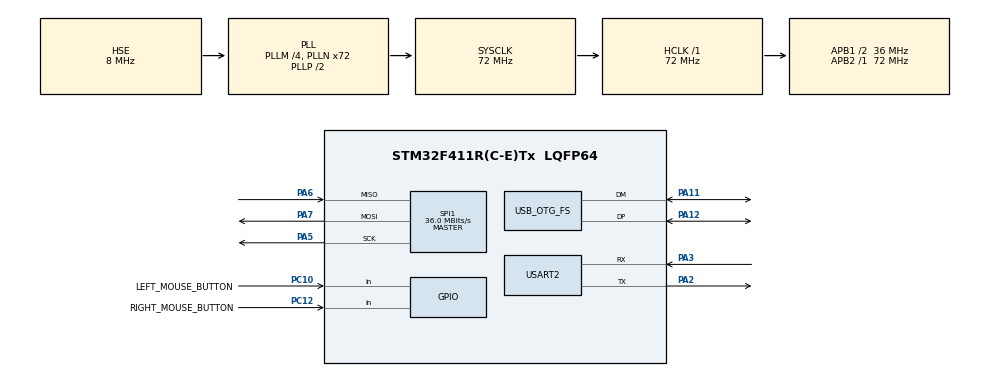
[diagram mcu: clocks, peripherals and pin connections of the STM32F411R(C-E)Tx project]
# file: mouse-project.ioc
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Mcu.Family=STM32F4
Mcu.Name=STM32F411R(C-E)Tx
Mcu.Package=LQFP64
NVIC.OTG_FS_IRQn=true\:0\:0\:false\:false\:true\:true\:true\:true
NVIC.PriorityGroup=NVIC_PRIORITYGROUP_4
PA11.Mode=Device_Only
PA11.Signal=USB_OTG_FS_DM
PA12.Mode=Device_Only
PA12.Signal=USB_OTG_FS_DP
PA2.Mode=Asynchronous
PA2.Signal=USART2_TX
PA3.Mode=Asynchronous
PA3.Signal=USART2_RX
PA5.Mode=Full_Duplex_Master
PA5.Signal=SPI1_SCK
PA6.Mode=Full_Duplex_Master
PA6.Signal=SPI1_MISO
PA7.Mode=Full_Duplex_Master
PA7.Signal=SPI1_MOSI
PC10.GPIO_Label=LEFT_MOUSE_BUTTON
PC10.Signal=GPIO_Input
PC12.GPIO_Label=RIGHT_MOUSE_BUTTON
PC12.Signal=GPIO_Input
PH0\ -\ OSC_IN.Mode=HSE-External-Clock-Source
PH0\ -\ OSC_IN.Signal=RCC_OSC_IN
PH1\ -\ OSC_OUT.Mode=HSE-External-Clock-Source
PH1\ -\ OSC_OUT.Signal=RCC_OSC_OUT
ProjectManager.HeapSize=0x200
ProjectManager.StackSize=0x400
ProjectManager.TargetToolchain=STM32CubeIDE
RCC.48MHZClocksFreq_Value=48000000
RCC.AHBFreq_Value=72000000
RCC.APB1CLKDivider=RCC_HCLK_DIV2
RCC.APB1Freq_Value=36000000
RCC.APB1TimFreq_Value=72000000
RCC.APB2Freq_Value=72000000
RCC.APB2TimFreq_Value=72000000
RCC.CortexFreq_Value=72000000
RCC.HCLKFreq_Value=72000000
RCC.HSE_VALUE=8000000
RCC.HSI_VALUE=16000000
RCC.LSE_VALUE=32768
RCC.PLLM=4
RCC.PLLN=72
RCC.PLLQ=3
RCC.SYSCLKFreq_VALUE=72000000
RCC.SYSCLKSource=RCC_SYSCLKSOURCE_PLLCLK
RCC.VCOOutputFreq_Value=144000000
SPI1.CLKPhase=SPI_PHASE_2EDGE
SPI1.CLKPolarity=SPI_POLARITY_HIGH
SPI1.CalculateBaudRate=36.0 MBits/s
SPI1.Direction=SPI_DIRECTION_2LINES
SPI1.Mode=SPI_MODE_MASTER
SPI1.VirtualType=VM_MASTER
USART2.VirtualMode=VM_ASYNC
USB_OTG_FS.VirtualMode=Device_Only
board=custom

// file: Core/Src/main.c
/* USER CODE BEGIN Header */
/**
  ******************************************************************************
  * @file           : main.c
  * @brief          : Main program body
  ******************************************************************************
  * @attention
  *
  * Copyright (c) 2026 STMicroelectronics.
  * All rights reserved.
  *
  * This software is licensed under terms that can be found in the LICENSE file
  * in the root directory of this software component.
  * If no LICENSE file comes with this software, it is provided AS-IS.
  *
  ******************************************************************************
  */
/* USER CODE END Header */
#include "main.h"
#include "mouse_driver.h"

SPI_HandleTypeDef hspi1;

UART_HandleTypeDef huart2;

PCD_HandleTypeDef hpcd_USB_OTG_FS;

void SystemClock_Config(void);
static void MX_GPIO_Init(void);
static void MX_SPI1_Init(void);
static void MX_USART2_UART_Init(void);
static void MX_USB_OTG_FS_PCD_Init(void);

int main(void)
{

  /* MCU Configuration--------------------------------------------------------*/

  /* Reset of all peripherals, Initializes the Flash interface and the Systick. */
  HAL_Init();

  /* Configure the system clock */
  SystemClock_Config();

  /* Initialize all configured peripherals */
  MX_GPIO_Init();
  MX_SPI1_Init();
  MX_USART2_UART_Init();
  MX_USB_OTG_FS_PCD_Init();
  /* USER CODE BEGIN 2 */
  //unsigned char uart_message[] = "Hello, world!\r\n";

  /* USER CODE END 2 */

  /* Infinite loop */
  /* USER CODE BEGIN WHILE */
  while (1)
  {
	  //HAL_UART_Transmit(&huart2, (uint8_t*) uart_message, sizeof(uart_message) - 1, 100);
    /* USER CODE END WHILE */

  }
}

void SystemClock_Config(void)
{
  RCC_OscInitTypeDef RCC_OscInitStruct = {0};
  RCC_ClkInitTypeDef RCC_ClkInitStruct = {0};

  /** Configure the main internal regulator output voltage
  */
  __HAL_RCC_PWR_CLK_ENABLE();
  __HAL_PWR_VOLTAGESCALING_CONFIG(PWR_REGULATOR_VOLTAGE_SCALE1);

  /** Initializes the RCC Oscillators according to the specified parameters
  * in the RCC_OscInitTypeDef structure.
  */
  RCC_OscInitStruct.OscillatorType = RCC_OSCILLATORTYPE_HSE;
  RCC_OscInitStruct.HSEState = RCC_HSE_BYPASS;
  RCC_OscInitStruct.PLL.PLLState = RCC_PLL_ON;
  RCC_OscInitStruct.PLL.PLLSource = RCC_PLLSOURCE_HSE;
  RCC_OscInitStruct.PLL.PLLM = 4;
  RCC_OscInitStruct.PLL.PLLN = 72;
  RCC_OscInitStruct.PLL.PLLP = RCC_PLLP_DIV2;
  RCC_OscInitStruct.PLL.PLLQ = 3;
  if (HAL_RCC_OscConfig(&RCC_OscInitStruct) != HAL_OK)
  {
    Error_Handler();
  }

  /** Initializes the CPU, AHB and APB buses clocks
  */
  RCC_ClkInitStruct.ClockType = RCC_CLOCKTYPE_HCLK|RCC_CLOCKTYPE_SYSCLK
                              |RCC_CLOCKTYPE_PCLK1|RCC_CLOCKTYPE_PCLK2;
  RCC_ClkInitStruct.SYSCLKSource = RCC_SYSCLKSOURCE_PLLCLK;
  RCC_ClkInitStruct.AHBCLKDivider = RCC_SYSCLK_DIV1;
  RCC_ClkInitStruct.APB1CLKDivider = RCC_HCLK_DIV2;
  RCC_ClkInitStruct.APB2CLKDivider = RCC_HCLK_DIV1;

  if (HAL_RCC_ClockConfig(&RCC_ClkInitStruct, FLASH_LATENCY_2) != HAL_OK)
  {
    Error_Handler();
  }
}

static void MX_SPI1_Init(void)
{

  /* SPI1 parameter configuration*/
  hspi1.Instance = SPI1;
  hspi1.Init.Mode = SPI_MODE_MASTER;
  hspi1.Init.Direction = SPI_DIRECTION_2LINES;
  hspi1.Init.DataSize = SPI_DATASIZE_8BIT;
  hspi1.Init.CLKPolarity = SPI_POLARITY_HIGH;
  hspi1.Init.CLKPhase = SPI_PHASE_2EDGE;
  hspi1.Init.NSS = SPI_NSS_SOFT;
  hspi1.Init.BaudRatePrescaler = SPI_BAUDRATEPRESCALER_2;
  hspi1.Init.FirstBit = SPI_FIRSTBIT_MSB;
  hspi1.Init.TIMode = SPI_TIMODE_DISABLE;
  hspi1.Init.CRCCalculation = SPI_CRCCALCULATION_DISABLE;
  hspi1.Init.CRCPolynomial = 10;
  if (HAL_SPI_Init(&hspi1) != HAL_OK)
  {
    Error_Handler();
  }

}

static void MX_USART2_UART_Init(void)
{

  huart2.Instance = USART2;
  huart2.Init.BaudRate = 115200;
  huart2.Init.WordLength = UART_WORDLENGTH_8B;
  huart2.Init.StopBits = UART_STOPBITS_1;
  huart2.Init.Parity = UART_PARITY_NONE;
  huart2.Init.Mode = UART_MODE_TX_RX;
  huart2.Init.HwFlowCtl = UART_HWCONTROL_NONE;
  huart2.Init.OverSampling = UART_OVERSAMPLING_16;
  if (HAL_UART_Init(&huart2) != HAL_OK)
  {
    Error_Handler();
  }

}

static void MX_USB_OTG_FS_PCD_Init(void)
{

  hpcd_USB_OTG_FS.Instance = USB_OTG_FS;
  hpcd_USB_OTG_FS.Init.dev_endpoints = 4;
  hpcd_USB_OTG_FS.Init.speed = PCD_SPEED_FULL;
  hpcd_USB_OTG_FS.Init.dma_enable = DISABLE;
  hpcd_USB_OTG_FS.Init.phy_itface = PCD_PHY_EMBEDDED;
  hpcd_USB_OTG_FS.Init.Sof_enable = DISABLE;
  hpcd_USB_OTG_FS.Init.low_power_enable = DISABLE;
  hpcd_USB_OTG_FS.Init.lpm_enable = DISABLE;
  hpcd_USB_OTG_FS.Init.vbus_sensing_enable = DISABLE;
  hpcd_USB_OTG_FS.Init.use_dedicated_ep1 = DISABLE;
  if (HAL_PCD_Init(&hpcd_USB_OTG_FS) != HAL_OK)
  {
    Error_Handler();
  }
  /* USER CODE BEGIN USB_OTG_FS_Init 2 */
  USB_Start(&hpcd_USB_OTG_FS);

  /* USER CODE END USB_OTG_FS_Init 2 */

}

static void MX_GPIO_Init(void)
{
  GPIO_InitTypeDef GPIO_InitStruct = {0};

  /* GPIO Ports Clock Enable */
  __HAL_RCC_GPIOH_CLK_ENABLE();
  __HAL_RCC_GPIOA_CLK_ENABLE();
  __HAL_RCC_GPIOC_CLK_ENABLE();

  /*Configure GPIO pins : LEFT_MOUSE_BUTTON_Pin RIGHT_MOUSE_BUTTON_Pin */
  GPIO_InitStruct.Pin = LEFT_MOUSE_BUTTON_Pin|RIGHT_MOUSE_BUTTON_Pin;
  GPIO_InitStruct.Mode = GPIO_MODE_INPUT;
  GPIO_InitStruct.Pull = GPIO_NOPULL;
  HAL_GPIO_Init(GPIOC, &GPIO_InitStruct);

}

void Error_Handler(void)
{
  __disable_irq();
  while (1)
  {
  }
}
